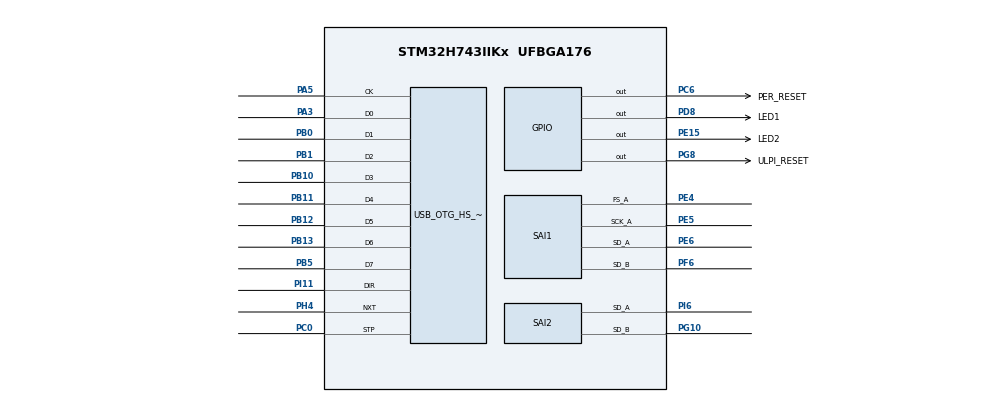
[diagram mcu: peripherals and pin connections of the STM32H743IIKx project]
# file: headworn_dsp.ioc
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CORTEX_M7.CPU_DCache=Enabled
CORTEX_M7.CPU_ICache=Enabled
Mcu.Family=STM32H7
Mcu.Name=STM32H743IIKx
Mcu.Package=UFBGA176
NVIC.OTG_HS_IRQn=true\:0\:0\:false\:false\:true\:false\:true
NVIC.PriorityGroup=NVIC_PRIORITYGROUP_4
PA3.Mode=Device_HS
PA3.Signal=USB_OTG_HS_ULPI_D0
PA5.Mode=Device_HS
PA5.Signal=USB_OTG_HS_ULPI_CK
PB0.Mode=Device_HS
PB0.Signal=USB_OTG_HS_ULPI_D1
PB1.Mode=Device_HS
PB1.Signal=USB_OTG_HS_ULPI_D2
PB10.Mode=Device_HS
PB10.Signal=USB_OTG_HS_ULPI_D3
PB11.Mode=Device_HS
PB11.Signal=USB_OTG_HS_ULPI_D4
PB12.Mode=Device_HS
PB12.Signal=USB_OTG_HS_ULPI_D5
PB13.Mode=Device_HS
PB13.Signal=USB_OTG_HS_ULPI_D6
PB5.Mode=Device_HS
PB5.Signal=USB_OTG_HS_ULPI_D7
PC0.Mode=Device_HS
PC0.Signal=USB_OTG_HS_ULPI_STP
PC6.GPIO_Label=PER_RESET
PC6.Signal=GPIO_Output
PD8.GPIO_Label=LED1
PD8.Signal=GPIO_Output
PE15.GPIO_Label=LED2
PE15.Signal=GPIO_Output
PE4.Mode=SAI_A_Master
PE4.Signal=SAI1_FS_A
PE5.Mode=SAI_A_Master
PE5.Signal=SAI1_SCK_A
PE6.Mode=SAI_A_Master
PE6.Signal=SAI1_SD_A
PF6.Mode=SAI_B_SyncSlave
PF6.Signal=SAI1_SD_B
PG10.Mode=SAI_B_SyncSlave
PG10.Signal=SAI2_SD_B
PG8.GPIO_Label=ULPI_RESET
PG8.Signal=GPIO_Output
PH0-OSC_IN\ (PH0).Mode=HSE-External-Clock-Source
PH0-OSC_IN\ (PH0).Signal=RCC_OSC_IN
PH1-OSC_OUT\ (PH1).Mode=HSE-External-Clock-Source
PH1-OSC_OUT\ (PH1).Signal=RCC_OSC_OUT
PH4.Mode=Device_HS
PH4.Signal=USB_OTG_HS_ULPI_NXT
PI11.Mode=Device_HS
PI11.Signal=USB_OTG_HS_ULPI_DIR
PI6.Mode=SAI_A_SyncSlave
PI6.Signal=SAI2_SD_A
ProjectManager.HeapSize=0x200
ProjectManager.StackSize=0x400
ProjectManager.TargetToolchain=STM32CubeIDE
RCC.ADCFreq_Value=48375000
RCC.APB1Freq_Value=100000000
RCC.APB2Freq_Value=100000000
RCC.APB3Freq_Value=100000000
RCC.APB4Freq_Value=100000000
RCC.CortexFreq_Value=400000000
RCC.D1PPRE=RCC_APB3_DIV2
RCC.D2PPRE1=RCC_APB1_DIV2
RCC.D2PPRE2=RCC_APB2_DIV2
RCC.D3PPRE=RCC_APB4_DIV2
RCC.DIVM1=3
RCC.DIVN1=100
RCC.HCLKFreq_Value=200000000
RCC.HPRE=RCC_HCLK_DIV2
RCC.HSE_VALUE=24000000
RCC.PLLSourceVirtual=RCC_PLLSOURCE_HSE
RCC.SYSCLKFreq_VALUE=400000000
RCC.SYSCLKSource=RCC_SYSCLKSOURCE_PLLCLK
RCC.USBFreq_Value=400000000
SAI1.ErrorAudioFreq-SAI_A_Master=1.72 %
SAI1.Instance-SAI_A_Master=SAI$Index_Block_A
SAI1.Instance-SAI_B_SyncSlave=SAI$Index_Block_B
SAI1.MClockEnable-SAI_A_Master=SAI_MASTERCLOCK_DISABLE
SAI1.RealAudioFreq-SAI_A_Master=195.312 KHz
SAI1.VirtualMode-SAI_A_Master=VM_MASTER
SAI1.VirtualMode-SAI_B_SyncSlave=VM_SLAVE
SAI2.Instance-SAI_A_SyncSlave=SAI$Index_Block_A
SAI2.Instance-SAI_B_SyncSlave=SAI$Index_Block_B
SAI2.Synchro_B=SAI_SYNCHRONOUS_EXT_SAI1
SAI2.VirtualMode-SAI_A_SyncSlave=VM_SLAVE
SAI2.VirtualMode-SAI_B_SyncSlave=VM_SLAVE
TIM2.AutoReloadPreload=TIM_AUTORELOAD_PRELOAD_ENABLE
TIM2.Period=0xffffffff
USB_DEVICE.CLASS_NAME_HS=CDC
USB_DEVICE.MANUFACTURER_STRING-CDC_HS=Caleb Crome
USB_DEVICE.PRODUCT_STRING_CDC_HS=Headworn COM Port
USB_DEVICE.VirtualMode-CDC_HS=Cdc
USB_DEVICE.VirtualModeHS=Cdc_HS
USB_OTG_HS.VirtualMode-Device_HS=Device_HS
VP_SAI1_VP_$IpInstance_SYNCHRO_EXTERNAL.Mode=SynchroExternal
VP_TIM2_VS_ClockSourceINT.Mode=Internal
VP_USB_DEVICE_VS_USB_DEVICE_CDC_HS.Mode=CDC_HS
board=custom

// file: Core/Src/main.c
/* USER CODE BEGIN Header */
/**
  ******************************************************************************
  * @file           : main.c
  * @brief          : Main program body
  ******************************************************************************
  * @attention
  *
  * <h2><center>&copy; Copyright (c) 2019 STMicroelectronics.
  * All rights reserved.</center></h2>
  *
  * This software component is licensed by ST under BSD 3-Clause license,
  * the "License"; You may not use this file except in compliance with the
  * License. You may obtain a copy of the License at:
  *                        opensource.org/licenses/BSD-3-Clause
  *
  ******************************************************************************
  */
/* USER CODE END Header */

#include "main.h"
#include "usb_device.h"

/* USER CODE BEGIN Includes */
#include "arm_math.h"

/* USER CODE END Includes */

SAI_HandleTypeDef hsai_BlockA1;
SAI_HandleTypeDef hsai_BlockB1;
SAI_HandleTypeDef hsai_BlockA2;
SAI_HandleTypeDef hsai_BlockB2;

TIM_HandleTypeDef htim2;

void SystemClock_Config(void);
static void MX_GPIO_Init(void);
static void MX_SAI1_Init(void);
static void MX_SAI2_Init(void);
static void MX_TIM2_Init(void);

/* USER CODE BEGIN 0 */
void dsp_test();
/* USER CODE END 0 */

int main(void)
{

  /* Enable I-Cache---------------------------------------------------------*/
  SCB_EnableICache();

  /* Enable D-Cache---------------------------------------------------------*/
  SCB_EnableDCache();

  /* MCU Configuration--------------------------------------------------------*/

  /* Reset of all peripherals, Initializes the Flash interface and the Systick. */
  HAL_Init();

  /* Configure the system clock */
  SystemClock_Config();

  /* Initialize all configured peripherals */
  MX_GPIO_Init();
  MX_SAI1_Init();
  MX_SAI2_Init();
  MX_USB_DEVICE_Init();
  MX_TIM2_Init();

  /* Infinite loop */
  /* USER CODE BEGIN WHILE */
  dsp_test();
  while (1)
  {

    /* USER CODE END WHILE */

  }
}

void SystemClock_Config(void)
{
  RCC_OscInitTypeDef RCC_OscInitStruct = {0};
  RCC_ClkInitTypeDef RCC_ClkInitStruct = {0};
  RCC_PeriphCLKInitTypeDef PeriphClkInitStruct = {0};

  /** Supply configuration update enable
  */
  HAL_PWREx_ConfigSupply(PWR_LDO_SUPPLY);
  /** Configure the main internal regulator output voltage
  */
  __HAL_PWR_VOLTAGESCALING_CONFIG(PWR_REGULATOR_VOLTAGE_SCALE1);

  while(!__HAL_PWR_GET_FLAG(PWR_FLAG_VOSRDY)) {}
  /** Initializes the CPU, AHB and APB busses clocks
  */
  RCC_OscInitStruct.OscillatorType = RCC_OSCILLATORTYPE_HSE;
  RCC_OscInitStruct.HSEState = RCC_HSE_BYPASS;
  RCC_OscInitStruct.PLL.PLLState = RCC_PLL_ON;
  RCC_OscInitStruct.PLL.PLLSource = RCC_PLLSOURCE_HSE;
  RCC_OscInitStruct.PLL.PLLM = 3;
  RCC_OscInitStruct.PLL.PLLN = 100;
  RCC_OscInitStruct.PLL.PLLP = 2;
  RCC_OscInitStruct.PLL.PLLQ = 2;
  RCC_OscInitStruct.PLL.PLLR = 2;
  RCC_OscInitStruct.PLL.PLLRGE = RCC_PLL1VCIRANGE_3;
  RCC_OscInitStruct.PLL.PLLVCOSEL = RCC_PLL1VCOWIDE;
  RCC_OscInitStruct.PLL.PLLFRACN = 0;
  if (HAL_RCC_OscConfig(&RCC_OscInitStruct) != HAL_OK)
  {
    Error_Handler();
  }
  /** Initializes the CPU, AHB and APB busses clocks
  */
  RCC_ClkInitStruct.ClockType = RCC_CLOCKTYPE_HCLK|RCC_CLOCKTYPE_SYSCLK
                              |RCC_CLOCKTYPE_PCLK1|RCC_CLOCKTYPE_PCLK2
                              |RCC_CLOCKTYPE_D3PCLK1|RCC_CLOCKTYPE_D1PCLK1;
  RCC_ClkInitStruct.SYSCLKSource = RCC_SYSCLKSOURCE_PLLCLK;
  RCC_ClkInitStruct.SYSCLKDivider = RCC_SYSCLK_DIV1;
  RCC_ClkInitStruct.AHBCLKDivider = RCC_HCLK_DIV2;
  RCC_ClkInitStruct.APB3CLKDivider = RCC_APB3_DIV2;
  RCC_ClkInitStruct.APB1CLKDivider = RCC_APB1_DIV2;
  RCC_ClkInitStruct.APB2CLKDivider = RCC_APB2_DIV2;
  RCC_ClkInitStruct.APB4CLKDivider = RCC_APB4_DIV2;

  if (HAL_RCC_ClockConfig(&RCC_ClkInitStruct, FLASH_LATENCY_2) != HAL_OK)
  {
    Error_Handler();
  }
  PeriphClkInitStruct.PeriphClockSelection = RCC_PERIPHCLK_SAI2|RCC_PERIPHCLK_SAI1;
  PeriphClkInitStruct.Sai1ClockSelection = RCC_SAI1CLKSOURCE_PLL;
  PeriphClkInitStruct.Sai23ClockSelection = RCC_SAI23CLKSOURCE_PLL;
  if (HAL_RCCEx_PeriphCLKConfig(&PeriphClkInitStruct) != HAL_OK)
  {
    Error_Handler();
  }
}

static void MX_SAI1_Init(void)
{

  hsai_BlockA1.Instance = SAI1_Block_A;
  hsai_BlockA1.Init.Protocol = SAI_FREE_PROTOCOL;
  hsai_BlockA1.Init.AudioMode = SAI_MODEMASTER_TX;
  hsai_BlockA1.Init.DataSize = SAI_DATASIZE_8;
  hsai_BlockA1.Init.FirstBit = SAI_FIRSTBIT_MSB;
  hsai_BlockA1.Init.ClockStrobing = SAI_CLOCKSTROBING_FALLINGEDGE;
  hsai_BlockA1.Init.Synchro = SAI_ASYNCHRONOUS;
  hsai_BlockA1.Init.OutputDrive = SAI_OUTPUTDRIVE_DISABLE;
  hsai_BlockA1.Init.NoDivider = SAI_MASTERDIVIDER_ENABLE;
  hsai_BlockA1.Init.FIFOThreshold = SAI_FIFOTHRESHOLD_EMPTY;
  hsai_BlockA1.Init.AudioFrequency = SAI_AUDIO_FREQUENCY_192K;
  hsai_BlockA1.Init.SynchroExt = SAI_SYNCEXT_DISABLE;
  hsai_BlockA1.Init.MonoStereoMode = SAI_STEREOMODE;
  hsai_BlockA1.Init.CompandingMode = SAI_NOCOMPANDING;
  hsai_BlockA1.Init.TriState = SAI_OUTPUT_NOTRELEASED;
  hsai_BlockA1.Init.PdmInit.Activation = DISABLE;
  hsai_BlockA1.Init.PdmInit.MicPairsNbr = 1;
  hsai_BlockA1.Init.PdmInit.ClockEnable = SAI_PDM_CLOCK1_ENABLE;
  hsai_BlockA1.FrameInit.FrameLength = 8;
  hsai_BlockA1.FrameInit.ActiveFrameLength = 1;
  hsai_BlockA1.FrameInit.FSDefinition = SAI_FS_STARTFRAME;
  hsai_BlockA1.FrameInit.FSPolarity = SAI_FS_ACTIVE_LOW;
  hsai_BlockA1.FrameInit.FSOffset = SAI_FS_FIRSTBIT;
  hsai_BlockA1.SlotInit.FirstBitOffset = 0;
  hsai_BlockA1.SlotInit.SlotSize = SAI_SLOTSIZE_DATASIZE;
  hsai_BlockA1.SlotInit.SlotNumber = 1;
  hsai_BlockA1.SlotInit.SlotActive = 0x00000000;
  if (HAL_SAI_Init(&hsai_BlockA1) != HAL_OK)
  {
    Error_Handler();
  }
  hsai_BlockB1.Instance = SAI1_Block_B;
  hsai_BlockB1.Init.Protocol = SAI_FREE_PROTOCOL;
  hsai_BlockB1.Init.AudioMode = SAI_MODESLAVE_RX;
  hsai_BlockB1.Init.DataSize = SAI_DATASIZE_8;
  hsai_BlockB1.Init.FirstBit = SAI_FIRSTBIT_MSB;
  hsai_BlockB1.Init.ClockStrobing = SAI_CLOCKSTROBING_FALLINGEDGE;
  hsai_BlockB1.Init.Synchro = SAI_SYNCHRONOUS;
  hsai_BlockB1.Init.OutputDrive = SAI_OUTPUTDRIVE_DISABLE;
  hsai_BlockB1.Init.FIFOThreshold = SAI_FIFOTHRESHOLD_EMPTY;
  hsai_BlockB1.Init.SynchroExt = SAI_SYNCEXT_DISABLE;
  hsai_BlockB1.Init.MonoStereoMode = SAI_STEREOMODE;
  hsai_BlockB1.Init.CompandingMode = SAI_NOCOMPANDING;
  hsai_BlockB1.Init.TriState = SAI_OUTPUT_NOTRELEASED;
  hsai_BlockB1.Init.PdmInit.Activation = DISABLE;
  hsai_BlockB1.Init.PdmInit.MicPairsNbr = 1;
  hsai_BlockB1.Init.PdmInit.ClockEnable = SAI_PDM_CLOCK1_ENABLE;
  hsai_BlockB1.FrameInit.FrameLength = 8;
  hsai_BlockB1.FrameInit.ActiveFrameLength = 1;
  hsai_BlockB1.FrameInit.FSDefinition = SAI_FS_STARTFRAME;
  hsai_BlockB1.FrameInit.FSPolarity = SAI_FS_ACTIVE_LOW;
  hsai_BlockB1.FrameInit.FSOffset = SAI_FS_FIRSTBIT;
  hsai_BlockB1.SlotInit.FirstBitOffset = 0;
  hsai_BlockB1.SlotInit.SlotSize = SAI_SLOTSIZE_DATASIZE;
  hsai_BlockB1.SlotInit.SlotNumber = 1;
  hsai_BlockB1.SlotInit.SlotActive = 0x00000000;
  if (HAL_SAI_Init(&hsai_BlockB1) != HAL_OK)
  {
    Error_Handler();
  }

}

static void MX_SAI2_Init(void)
{

  hsai_BlockA2.Instance = SAI2_Block_A;
  hsai_BlockA2.Init.Protocol = SAI_FREE_PROTOCOL;
  hsai_BlockA2.Init.AudioMode = SAI_MODESLAVE_RX;
  hsai_BlockA2.Init.DataSize = SAI_DATASIZE_8;
  hsai_BlockA2.Init.FirstBit = SAI_FIRSTBIT_MSB;
  hsai_BlockA2.Init.ClockStrobing = SAI_CLOCKSTROBING_FALLINGEDGE;
  hsai_BlockA2.Init.Synchro = SAI_SYNCHRONOUS;
  hsai_BlockA2.Init.OutputDrive = SAI_OUTPUTDRIVE_DISABLE;
  hsai_BlockA2.Init.FIFOThreshold = SAI_FIFOTHRESHOLD_EMPTY;
  hsai_BlockA2.Init.MonoStereoMode = SAI_STEREOMODE;
  hsai_BlockA2.Init.CompandingMode = SAI_NOCOMPANDING;
  hsai_BlockA2.Init.TriState = SAI_OUTPUT_NOTRELEASED;
  hsai_BlockA2.Init.PdmInit.Activation = DISABLE;
  hsai_BlockA2.Init.PdmInit.MicPairsNbr = 1;
  hsai_BlockA2.Init.PdmInit.ClockEnable = SAI_PDM_CLOCK1_ENABLE;
  hsai_BlockA2.FrameInit.FrameLength = 8;
  hsai_BlockA2.FrameInit.ActiveFrameLength = 1;
  hsai_BlockA2.FrameInit.FSDefinition = SAI_FS_STARTFRAME;
  hsai_BlockA2.FrameInit.FSPolarity = SAI_FS_ACTIVE_LOW;
  hsai_BlockA2.FrameInit.FSOffset = SAI_FS_FIRSTBIT;
  hsai_BlockA2.SlotInit.FirstBitOffset = 0;
  hsai_BlockA2.SlotInit.SlotSize = SAI_SLOTSIZE_DATASIZE;
  hsai_BlockA2.SlotInit.SlotNumber = 1;
  hsai_BlockA2.SlotInit.SlotActive = 0x00000000;
  if (HAL_SAI_Init(&hsai_BlockA2) != HAL_OK)
  {
    Error_Handler();
  }
  hsai_BlockB2.Instance = SAI2_Block_B;
  hsai_BlockB2.Init.Protocol = SAI_FREE_PROTOCOL;
  hsai_BlockB2.Init.AudioMode = SAI_MODESLAVE_RX;
  hsai_BlockB2.Init.DataSize = SAI_DATASIZE_8;
  hsai_BlockB2.Init.FirstBit = SAI_FIRSTBIT_MSB;
  hsai_BlockB2.Init.ClockStrobing = SAI_CLOCKSTROBING_FALLINGEDGE;
  hsai_BlockB2.Init.Synchro = SAI_SYNCHRONOUS_EXT_SAI1;
  hsai_BlockB2.Init.OutputDrive = SAI_OUTPUTDRIVE_DISABLE;
  hsai_BlockB2.Init.FIFOThreshold = SAI_FIFOTHRESHOLD_EMPTY;
  hsai_BlockB2.Init.MonoStereoMode = SAI_STEREOMODE;
  hsai_BlockB2.Init.CompandingMode = SAI_NOCOMPANDING;
  hsai_BlockB2.Init.TriState = SAI_OUTPUT_NOTRELEASED;
  hsai_BlockB2.Init.PdmInit.Activation = DISABLE;
  hsai_BlockB2.Init.PdmInit.MicPairsNbr = 1;
  hsai_BlockB2.Init.PdmInit.ClockEnable = SAI_PDM_CLOCK1_ENABLE;
  hsai_BlockB2.FrameInit.FrameLength = 8;
  hsai_BlockB2.FrameInit.ActiveFrameLength = 1;
  hsai_BlockB2.FrameInit.FSDefinition = SAI_FS_STARTFRAME;
  hsai_BlockB2.FrameInit.FSPolarity = SAI_FS_ACTIVE_LOW;
  hsai_BlockB2.FrameInit.FSOffset = SAI_FS_FIRSTBIT;
  hsai_BlockB2.SlotInit.FirstBitOffset = 0;
  hsai_BlockB2.SlotInit.SlotSize = SAI_SLOTSIZE_DATASIZE;
  hsai_BlockB2.SlotInit.SlotNumber = 1;
  hsai_BlockB2.SlotInit.SlotActive = 0x00000000;
  if (HAL_SAI_Init(&hsai_BlockB2) != HAL_OK)
  {
    Error_Handler();
  }

}

static void MX_TIM2_Init(void)
{

  TIM_ClockConfigTypeDef sClockSourceConfig = {0};
  TIM_MasterConfigTypeDef sMasterConfig = {0};

  htim2.Instance = TIM2;
  htim2.Init.Prescaler = 0;
  htim2.Init.CounterMode = TIM_COUNTERMODE_UP;
  htim2.Init.Period = 0xffffffff;
  htim2.Init.ClockDivision = TIM_CLOCKDIVISION_DIV1;
  htim2.Init.AutoReloadPreload = TIM_AUTORELOAD_PRELOAD_ENABLE;
  if (HAL_TIM_Base_Init(&htim2) != HAL_OK)
  {
    Error_Handler();
  }
  sClockSourceConfig.ClockSource = TIM_CLOCKSOURCE_INTERNAL;
  if (HAL_TIM_ConfigClockSource(&htim2, &sClockSourceConfig) != HAL_OK)
  {
    Error_Handler();
  }
  sMasterConfig.MasterOutputTrigger = TIM_TRGO_RESET;
  sMasterConfig.MasterSlaveMode = TIM_MASTERSLAVEMODE_DISABLE;
  if (HAL_TIMEx_MasterConfigSynchronization(&htim2, &sMasterConfig) != HAL_OK)
  {
    Error_Handler();
  }

}

static void MX_GPIO_Init(void)
{
  GPIO_InitTypeDef GPIO_InitStruct = {0};

  /* GPIO Ports Clock Enable */
  __HAL_RCC_GPIOB_CLK_ENABLE();
  __HAL_RCC_GPIOE_CLK_ENABLE();
  __HAL_RCC_GPIOG_CLK_ENABLE();
  __HAL_RCC_GPIOI_CLK_ENABLE();
  __HAL_RCC_GPIOH_CLK_ENABLE();
  __HAL_RCC_GPIOC_CLK_ENABLE();
  __HAL_RCC_GPIOF_CLK_ENABLE();
  __HAL_RCC_GPIOA_CLK_ENABLE();
  __HAL_RCC_GPIOD_CLK_ENABLE();

  /*Configure GPIO pin Output Level */
  HAL_GPIO_WritePin(ULPI_RESET_GPIO_Port, ULPI_RESET_Pin, GPIO_PIN_RESET);

  /*Configure GPIO pin Output Level */
  HAL_GPIO_WritePin(PER_RESET_GPIO_Port, PER_RESET_Pin, GPIO_PIN_RESET);

  /*Configure GPIO pin Output Level */
  HAL_GPIO_WritePin(LED1_GPIO_Port, LED1_Pin, GPIO_PIN_RESET);

  /*Configure GPIO pin Output Level */
  HAL_GPIO_WritePin(LED2_GPIO_Port, LED2_Pin, GPIO_PIN_RESET);

  /*Configure GPIO pin : ULPI_RESET_Pin */
  GPIO_InitStruct.Pin = ULPI_RESET_Pin;
  GPIO_InitStruct.Mode = GPIO_MODE_OUTPUT_PP;
  GPIO_InitStruct.Pull = GPIO_NOPULL;
  GPIO_InitStruct.Speed = GPIO_SPEED_FREQ_LOW;
  HAL_GPIO_Init(ULPI_RESET_GPIO_Port, &GPIO_InitStruct);

  /*Configure GPIO pin : PER_RESET_Pin */
  GPIO_InitStruct.Pin = PER_RESET_Pin;
  GPIO_InitStruct.Mode = GPIO_MODE_OUTPUT_PP;
  GPIO_InitStruct.Pull = GPIO_NOPULL;
  GPIO_InitStruct.Speed = GPIO_SPEED_FREQ_LOW;
  HAL_GPIO_Init(PER_RESET_GPIO_Port, &GPIO_InitStruct);

  /*Configure GPIO pin : LED1_Pin */
  GPIO_InitStruct.Pin = LED1_Pin;
  GPIO_InitStruct.Mode = GPIO_MODE_OUTPUT_PP;
  GPIO_InitStruct.Pull = GPIO_NOPULL;
  GPIO_InitStruct.Speed = GPIO_SPEED_FREQ_LOW;
  HAL_GPIO_Init(LED1_GPIO_Port, &GPIO_InitStruct);

  /*Configure GPIO pin : LED2_Pin */
  GPIO_InitStruct.Pin = LED2_Pin;
  GPIO_InitStruct.Mode = GPIO_MODE_OUTPUT_PP;
  GPIO_InitStruct.Pull = GPIO_NOPULL;
  GPIO_InitStruct.Speed = GPIO_SPEED_FREQ_LOW;
  HAL_GPIO_Init(LED2_GPIO_Port, &GPIO_InitStruct);

}

void Error_Handler(void)
{
}

/************************ (C) COPYRIGHT STMicroelectronics *****END OF FILE****/
